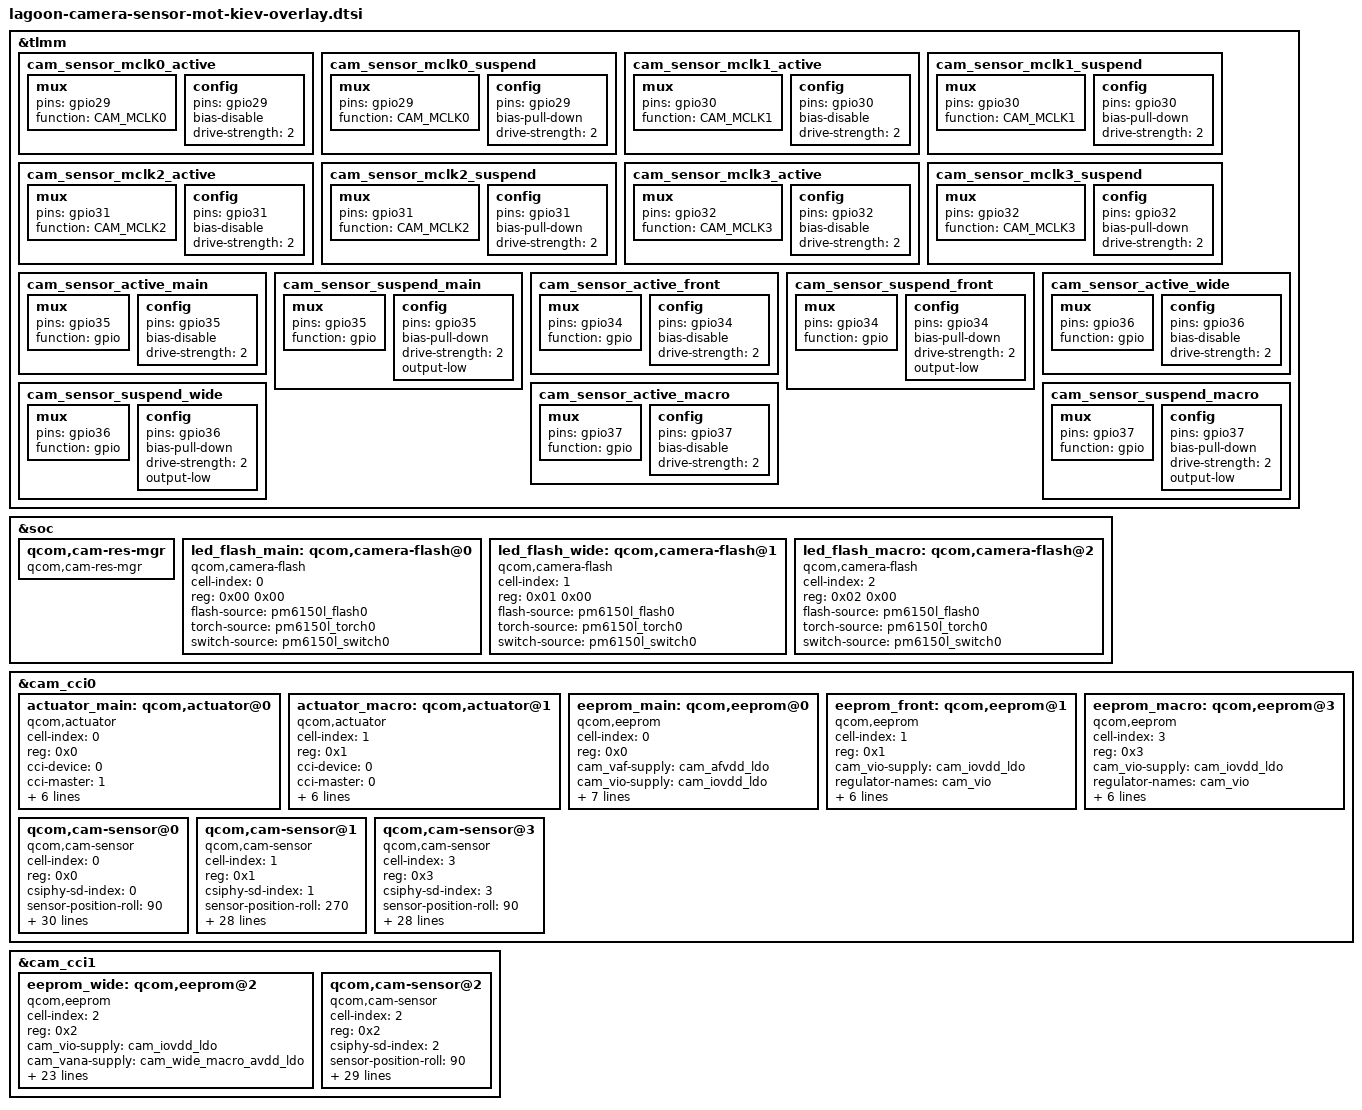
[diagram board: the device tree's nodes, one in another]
#include <dt-bindings/clock/qcom,camcc-lagoon.h>

&tlmm {
	cam_sensor_mclk0_active: cam_sensor_mclk0_active {
		/* MCLK0 */
		mux {
			pins = "gpio29";
			function = "CAM_MCLK0";
		};

		config {
			pins = "gpio29";
			bias-disable; /* No PULL */
			drive-strength = <2>; /* 2 MA */
		};
	};

	cam_sensor_mclk0_suspend: cam_sensor_mclk0_suspend {
		/* MCLK0 */
		mux {
			pins = "gpio29";
			function = "CAM_MCLK0";
		};

		config {
			pins = "gpio29";
			bias-pull-down; /* PULL DOWN */
			drive-strength = <2>; /* 2 MA */
		};
	};

	cam_sensor_mclk1_active: cam_sensor_mclk1_active {
		/* MCLK1 */
		mux {
			pins = "gpio30";
			function = "CAM_MCLK1";
		};

		config {
			pins = "gpio30";
			bias-disable; /* No PULL */
			drive-strength = <2>; /* 2 MA */
		};
	};

	cam_sensor_mclk1_suspend: cam_sensor_mclk1_suspend {
		/* MCLK1 */
		mux {
			pins = "gpio30";
			function = "CAM_MCLK1";
		};

		config {
			pins = "gpio30";
			bias-pull-down; /* PULL DOWN */
			drive-strength = <2>; /* 2 MA */
		};
	};

	cam_sensor_mclk2_active: cam_sensor_mclk2_active {
		/* MCLK2 */
		mux {
			pins = "gpio31";
			function = "CAM_MCLK2";
		};

		config {
			pins = "gpio31";
			bias-disable; /* No PULL */
			drive-strength = <2>; /* 2 MA */
		};
	};

	cam_sensor_mclk2_suspend: cam_sensor_mclk2_suspend {
		/* MCLK2 */
		mux {
			pins = "gpio31";
			function = "CAM_MCLK2";
		};

		config {
			pins = "gpio31";
			bias-pull-down; /* PULL DOWN */
			drive-strength = <2>; /* 2 MA */
		};
	};

	cam_sensor_mclk3_active: cam_sensor_mclk3_active {
		/* MCLK3 */
		mux {
			pins = "gpio32";
			function = "CAM_MCLK3";
		};

		config {
			pins = "gpio32";
			bias-disable; /* No PULL */
			drive-strength = <2>; /* 2 MA */
		};
	};

	cam_sensor_mclk3_suspend: cam_sensor_mclk3_suspend {
		/* MCLK3 */
		mux {
			pins = "gpio32";
			function = "CAM_MCLK3";
		};

		config {
			pins = "gpio32";
			bias-pull-down; /* PULL DOWN */
			drive-strength = <2>; /* 2 MA */
		};
	};

	cam_sensor_active_main: cam_sensor_active_main {
		/* ream main reset */
		mux {
			pins = "gpio35";
			function = "gpio";
		};

		config {
			pins = "gpio35";
			bias-disable; /* No PULL */
			drive-strength = <2>; /* 2 MA */
		};
	};

	cam_sensor_suspend_main: cam_sensor_suspend_main {
		/* ream main reset */
		mux {
			pins = "gpio35";
			function = "gpio";
		};

		config {
			pins = "gpio35";
			bias-pull-down; /* PULL DOWN */
			drive-strength = <2>; /* 2 MA */
			output-low;
		};
	};

	cam_sensor_active_front: cam_sensor_active_front {
		/* front reset */
		mux {
			pins = "gpio34";
			function = "gpio";
		};

		config {
			pins = "gpio34";
			bias-disable; /* No PULL */
			drive-strength = <2>; /* 2 MA */
		};
	};

	cam_sensor_suspend_front: cam_sensor_suspend_front {
		/* front reset */
		mux {
			pins = "gpio34";
			function = "gpio";
		};

		config {
			pins = "gpio34";
			bias-pull-down; /* PULL DOWN */
			drive-strength = <2>; /* 2 MA */
			output-low;
		};
	};

	cam_sensor_active_wide: cam_sensor_active_wide {
		/* rear wide reset */
		mux {
			pins = "gpio36";
			function = "gpio";
		};

		config {
			pins = "gpio36";
			bias-disable; /* No PULL */
			drive-strength = <2>; /* 2 MA */
		};
	};

	cam_sensor_suspend_wide: cam_sensor_suspend_wide {
		/* rear wide reset */
		mux {
			pins = "gpio36";
			function = "gpio";
		};

		config {
			pins = "gpio36";
			bias-pull-down; /* PULL DOWN */
			drive-strength = <2>; /* 2 MA */
			output-low;
		};
	};

	cam_sensor_active_macro: cam_sensor_active_macro {
		/* rear macro reset */
		mux {
			pins = "gpio37";
			function = "gpio";
		};

		config {
			pins = "gpio37";
			bias-disable; /* No PULL */
			drive-strength = <2>; /* 2 MA */
		};
	};

	cam_sensor_suspend_macro: cam_sensor_suspend_macro {
		/* rear macro reset */
		mux {
			pins = "gpio37";
			function = "gpio";
		};

		config {
			pins = "gpio37";
			bias-pull-down; /* PULL DOWN */
			drive-strength = <2>; /* 2 MA */
			output-low;
		};
	};
};

&soc {
	qcom,cam-res-mgr {
		compatible = "qcom,cam-res-mgr";
		status = "ok";
	};

	led_flash_main: qcom,camera-flash@0 {
		cell-index = <0>;
		reg = <0x00 0x00>;
		compatible = "qcom,camera-flash";
		flash-source = <&pm6150l_flash0>;
		torch-source = <&pm6150l_torch0>;
		switch-source = <&pm6150l_switch0>;
		status = "ok";
	};

	led_flash_wide: qcom,camera-flash@1 {
		cell-index = <1>;
		reg = <0x01 0x00>;
		compatible = "qcom,camera-flash";
		flash-source = <&pm6150l_flash0>;
		torch-source = <&pm6150l_torch0>;
		switch-source = <&pm6150l_switch0>;
		status = "ok";
	};

	led_flash_macro: qcom,camera-flash@2 {
		cell-index = <2>;
		reg = <0x02 0x00>;
		compatible = "qcom,camera-flash";
		flash-source = <&pm6150l_flash0>;
		torch-source = <&pm6150l_torch0>;
		switch-source = <&pm6150l_switch0>;
		status = "ok";
	};
};

&cam_cci0 {
	actuator_main: qcom,actuator@0 {
		cell-index = <0>;
		reg = <0x0>;
		compatible = "qcom,actuator";
		cci-device = <0>;
		cci-master = <1>;
		cam_vaf-supply = <&cam_afvdd_ldo>;
		regulator-names = "cam_vaf";
		rgltr-cntrl-support;
		rgltr-min-voltage = <2800000>;
		rgltr-max-voltage = <2800000>;
		rgltr-load-current = <100000>;
		status = "ok";
	};

	actuator_macro: qcom,actuator@1 {
		cell-index = <1>;
		reg = <0x1>;
		compatible = "qcom,actuator";
		cci-device = <0>;
		cci-master = <0>;
		cam_vaf-supply = <&cam_afvdd_ldo>;
		regulator-names = "cam_vaf";
		rgltr-cntrl-support;
		rgltr-min-voltage = <2800000>;
		rgltr-max-voltage = <2800000>;
		rgltr-load-current = <100000>;
		status = "ok";
	};

	eeprom_main: qcom,eeprom@0 {
		cell-index = <0>;
		reg = <0x0>;
		compatible = "qcom,eeprom";
		cam_vaf-supply = <&cam_afvdd_ldo>;
		cam_vio-supply = <&cam_iovdd_ldo>;
		regulator-names = "cam_vaf", "cam_vio";
		rgltr-cntrl-support;
		rgltr-min-voltage = <2800000 1800000>;
		rgltr-max-voltage = <2800000 1800000>;
		rgltr-load-current = <100000 0>;
		cci-device = <0>;
		cci-master = <1>;
		status = "ok";
	};

	eeprom_front: qcom,eeprom@1 {
		cell-index = <1>;
		reg = <0x1>;
		compatible = "qcom,eeprom";
		cam_vio-supply = <&cam_iovdd_ldo>;
		regulator-names = "cam_vio";
		rgltr-cntrl-support;
		rgltr-min-voltage = <1800000>;
		rgltr-max-voltage = <1800000>;
		rgltr-load-current = <0>;
		cci-device = <0>;
		cci-master = <0>;
		status = "ok";
	};

	eeprom_macro: qcom,eeprom@3 {
		cell-index = <3>;
		reg = <0x3>;
		compatible = "qcom,eeprom";
		cam_vio-supply = <&cam_iovdd_ldo>;
		regulator-names = "cam_vio";
		rgltr-cntrl-support;
		rgltr-min-voltage = <1800000>;
		rgltr-max-voltage = <1800000>;
		rgltr-load-current = <0>;
		cci-device = <0>;
		cci-master = <0>;
		status = "ok";
	};

	qcom,cam-sensor@0 {
		cell-index = <0>;
		compatible = "qcom,cam-sensor";
		reg = <0x0>;
		csiphy-sd-index = <0>;
		sensor-position-roll = <90>;
		sensor-position-pitch = <0>;
		sensor-position-yaw = <180>;
		led-flash-src = <&led_flash_main>;
		actuator-src = <&actuator_main>;
		eeprom-src = <&eeprom_main>;
		cam_vio-supply = <&cam_iovdd_ldo>;
		cam_vana-supply = <&cam_main_front_avdd_ldo>;
		cam_vdig-supply = <&cam_main_dvdd_ldo>;
		cam_clk-supply = <&cam_cc_titan_top_gdsc>;
		regulator-names = "cam_vio", "cam_vana", "cam_vdig",
			"cam_clk";
		rgltr-cntrl-support;
		rgltr-min-voltage = <1800000 2800000 1050000 0>;
		rgltr-max-voltage = <1800000 2800000 1050000 0>;
		rgltr-load-current = <0 2000000 105000 0>;
		gpio-no-mux = <0>;
		pinctrl-names = "cam_default", "cam_suspend";
		pinctrl-0 = <&cam_sensor_mclk0_active
				&cam_sensor_active_main>;
		pinctrl-1 = <&cam_sensor_mclk0_suspend
				&cam_sensor_suspend_main>;
		gpios = <&tlmm 29 0>,
			<&tlmm 35 0>;
		gpio-reset = <1>;
		gpio-req-tbl-num = <0 1>;
		gpio-req-tbl-flags = <1 0>;
		gpio-req-tbl-label = "CAMIF_MCLK0",
					"CAM_RESET0";
		cci-device = <0>;
		cci-master = <1>;
		status = "ok";
		clocks = <&camcc CAM_CC_MCLK0_CLK>;
		clock-names = "cam_clk";
		clock-cntl-level = "turbo";
		clock-rates = <24000000>;
	};

	qcom,cam-sensor@1 {
		cell-index = <1>;
		compatible = "qcom,cam-sensor";
		reg = <0x1>;
		csiphy-sd-index = <1>;
		sensor-position-roll = <270>;
		sensor-position-pitch = <0>;
		sensor-position-yaw = <0>;
		eeprom-src = <&eeprom_front>;
		cam_vio-supply = <&cam_iovdd_ldo>;
		cam_vana-supply = <&cam_main_front_avdd_ldo>;
		cam_vdig-supply = <&cam_wide_front_dvdd_ldo>;
		cam_clk-supply = <&cam_cc_titan_top_gdsc>;
		regulator-names = "cam_vio", "cam_vana", "cam_vdig",
			"cam_clk";
		rgltr-cntrl-support;
		rgltr-min-voltage = <1800000 2800000 1200000 0>;
		rgltr-max-voltage = <1800000 2800000 1200000 0>;
		rgltr-load-current = <0 2000000 1200000 0>;
		gpio-no-mux = <0>;
		pinctrl-names = "cam_default", "cam_suspend";
		pinctrl-0 = <&cam_sensor_mclk2_active
				&cam_sensor_active_front>;
		pinctrl-1 = <&cam_sensor_mclk2_suspend
				&cam_sensor_suspend_front>;
		gpios = <&tlmm 31 0>,
			<&tlmm 34 0>;
		gpio-reset = <1>;
		gpio-req-tbl-num = <0 1>;
		gpio-req-tbl-flags = <1 0>;
		gpio-req-tbl-label = "CAMIF_MCLK2",
					"CAM_RESET2";
		cci-device = <0>;
		cci-master = <0>;
		status = "ok";
		clocks = <&camcc CAM_CC_MCLK2_CLK>;
		clock-names = "cam_clk";
		clock-cntl-level = "turbo";
		clock-rates = <24000000>;
	};

	qcom,cam-sensor@3 {
		cell-index = <3>;
		compatible = "qcom,cam-sensor";
		reg = <0x3>;
		csiphy-sd-index = <3>;
		sensor-position-roll = <90>;
		sensor-position-pitch = <0>;
		sensor-position-yaw = <180>;
		led-flash-src = <&led_flash_macro>;
		actuator-src = <&actuator_macro>;
		eeprom-src = <&eeprom_macro>;
		cam_vio-supply = <&cam_iovdd_ldo>;
		cam_vana-supply = <&cam_wide_macro_avdd_ldo>;
		cam_clk-supply = <&cam_cc_titan_top_gdsc>;
		regulator-names = "cam_vio", "cam_vana",
			"cam_clk";
		rgltr-cntrl-support;
		rgltr-min-voltage = <1800000 2800000 0>;
		rgltr-max-voltage = <1800000 2800000 0>;
		rgltr-load-current = <0 2000000 0>;
		gpio-no-mux = <0>;
		pinctrl-names = "cam_default", "cam_suspend";
		pinctrl-0 = <&cam_sensor_mclk3_active
				&cam_sensor_active_macro>;
		pinctrl-1 = <&cam_sensor_mclk3_suspend
				&cam_sensor_suspend_macro>;
		gpios = <&tlmm 32 0>,
			<&tlmm 37 0>;
		gpio-reset = <1>;
		gpio-req-tbl-num = <0 1>;
		gpio-req-tbl-flags = <1 0>;
		gpio-req-tbl-label = "CAMIF_MCLK3",
					"CAM_RESET3";
		cci-device = <0>;
		cci-master = <0>;
		status = "ok";
		clocks = <&camcc CAM_CC_MCLK3_CLK>;
		clock-names = "cam_clk";
		clock-cntl-level = "turbo";
		clock-rates = <24000000>;
	};
};

&cam_cci1 {
	eeprom_wide: qcom,eeprom@2 {
		cell-index = <2>;
		reg = <0x2>;
		compatible = "qcom,eeprom";
		cam_vio-supply = <&cam_iovdd_ldo>;
		cam_vana-supply = <&cam_wide_macro_avdd_ldo>;
		cam_vdig-supply = <&cam_wide_front_dvdd_ldo>;
		cam_clk-supply = <&cam_cc_titan_top_gdsc>;
		regulator-names = "cam_vio", "cam_vana", "cam_vdig",
			"cam_clk";
		rgltr-cntrl-support;
		rgltr-min-voltage = <1800000 2800000 1200000 0>;
		rgltr-max-voltage = <1800000 2800000 1200000 0>;
		rgltr-load-current = <0 2000000 1200000 0>;
		gpio-no-mux = <0>;
		pinctrl-names = "cam_default", "cam_suspend";
		pinctrl-0 = <&cam_sensor_mclk1_active
				&cam_sensor_active_wide>;
		pinctrl-1 = <&cam_sensor_mclk1_suspend
				&cam_sensor_suspend_wide>;
		gpios = <&tlmm 30 0>,
			<&tlmm 36 0>;
		gpio-reset = <1>;
		gpio-req-tbl-num = <0 1>;
		gpio-req-tbl-flags = <1 0>;
		gpio-req-tbl-label = "CAMIF_MCLK1",
					"CAM_RESET1";
		cci-device = <1>;
		cci-master = <0>;
		status = "ok";
		clocks = <&camcc CAM_CC_MCLK1_CLK>;
		clock-names = "cam_clk";
		clock-cntl-level = "turbo";
		clock-rates = <24000000>;
	};

	qcom,cam-sensor@2 {
		cell-index = <2>;
		compatible = "qcom,cam-sensor";
		reg = <0x2>;
		csiphy-sd-index = <2>;
		sensor-position-roll = <90>;
		sensor-position-pitch = <0>;
		sensor-position-yaw = <180>;
		led-flash-src = <&led_flash_wide>;
		eeprom-src = <&eeprom_wide>;
		cam_vio-supply = <&cam_iovdd_ldo>;
		cam_vana-supply = <&cam_wide_macro_avdd_ldo>;
		cam_vdig-supply = <&cam_wide_front_dvdd_ldo>;
		cam_clk-supply = <&cam_cc_titan_top_gdsc>;
		regulator-names = "cam_vio", "cam_vana", "cam_vdig",
			"cam_clk";
		rgltr-cntrl-support;
		rgltr-min-voltage = <1800000 2800000 1200000 0>;
		rgltr-max-voltage = <1800000 2800000 1200000 0>;
		rgltr-load-current = <0 2000000 1200000 0>;
		gpio-no-mux = <0>;
		pinctrl-names = "cam_default", "cam_suspend";
		pinctrl-0 = <&cam_sensor_mclk1_active
				&cam_sensor_active_wide>;
		pinctrl-1 = <&cam_sensor_mclk1_suspend
				&cam_sensor_suspend_wide>;
		gpios = <&tlmm 30 0>,
			<&tlmm 36 0>;
		gpio-reset = <1>;
		gpio-req-tbl-num = <0 1>;
		gpio-req-tbl-flags = <1 0>;
		gpio-req-tbl-label = "CAMIF_MCLK1",
					"CAM_RESET1";
		cci-device = <1>;
		cci-master = <0>;
		status = "ok";
		clocks = <&camcc CAM_CC_MCLK1_CLK>;
		clock-names = "cam_clk";
		clock-cntl-level = "turbo";
		clock-rates = <24000000>;
	};
};
